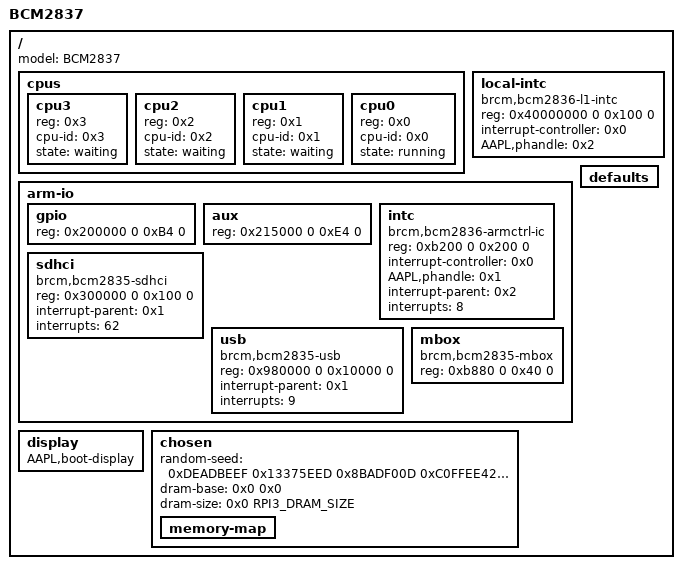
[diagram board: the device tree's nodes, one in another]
/dts-v1/;

/*
 * Base tree from FlorentRevest/xnu (devicetrees/rpi3.dts), extended with an
 * SD/MMC controller node and the BCM2836/2837 interrupt controllers.
 *
 * Register offsets/sizes/interrupt cells sourced from upstream Linux:
 *   arch/arm/boot/dts/broadcom/bcm283x.dtsi   (gpio, aux, sdhci, sdhost)
 *   arch/arm/boot/dts/broadcom/bcm2837.dtsi   (local_intc, armctrl-ic override)
 *
 * ROOT CAUSE FOUND AND FIXED (2026-08-13): the <bank irq> 2-cell interrupt
 * encoding this file used to carry over raw from the Linux DT was flagged
 * above as UNVERIFIED, and was in fact wrong - this is very likely why
 * BCM2837SDHCI never observed a real hardware interrupt despite BCM2837CPU's
 * IRQ cascade being otherwise correctly wired (see iokit/BCM2837SDHCI's own
 * "fRealInterruptHits stayed at 0" finding). Traced the real mechanism
 * directly in xnu source (iokit/Kernel/IODeviceTreeSupport.cpp's
 * IODTMapOneInterrupt() + iokit/Kernel/IOInterruptController.cpp's
 * registerInterrupt()): IODTMapOneInterrupt() stores a device's `interrupts`
 * property as a RAW, unmodified OSData blob (all `#interrupt-cells` words,
 * verbatim) - it does NOT combine multi-cell specifiers into anything. The
 * base IOInterruptController::registerInterrupt() then does
 * `vectorNumber = *(IOInterruptVectorNumber *)vectorData->getBytesNoCopy()`
 * - i.e. it blindly takes the FIRST 32-bit cell as the vector number and
 * nothing else, unless the concrete controller subclass overrides
 * registerInterrupt() to do its own multi-cell decode (BCM2837InterruptController
 * does not - see its own header comment, which already flagged this exact
 * gap as unverified). With `#interrupt-cells = <2>` and sdhci's
 * `interrupts = <2 30>`, this meant BCM2837SDHCI's real registered vector
 * number was **2** (the bare first cell) - landing in BCM2837InterruptController's
 * bank-1 range, nowhere near the real hardware bit (bank 2, bit 30 = flat
 * vector 62, per that driver's own bank*32+bit numbering) - so even if the
 * real interrupt line fires, it dispatches to a vector nothing ever
 * registered against, and is silently dropped. Fixed by making `intc`
 * single-cell (`#interrupt-cells = <1>`) and pre-flattening every consumer's
 * `interrupts` property to the already-combined vector number instead -
 * matches what `local-intc`'s own single-cell `interrupts = <8>` already
 * did correctly (single-cell is exactly what the base class's naive
 * first-cell-as-vector-number behavior needs), and avoids having to
 * override IOInterruptController::registerInterrupt() (large, sharing/
 * locking-sensitive base-class code) just to teach it a 2-cell convention.
 */

/ {
	#address-cells = <2>;
	#size-cells = <2>;

	/* Real, unmodified Apple IODTPlatformExpert::getMachineName()
	 * (iokit/Kernel/IOPlatformExpert.cpp) reads this exact property
	 * (gIODTModelKey == "model") off the root node's provider and
	 * returns false -- not a stub, real deprecated-but-still-live
	 * logic -- when it's absent, which is exactly what
	 * bsd/kern/kern_mib.c's real HW_MACHINE sysctl handler treats as a
	 * hard EINVAL (this board takes that file's non-XNU_TARGET_OS_OSX
	 * branch, since BCM2837 builds embedded/iPhoneOS, not macOS -- see
	 * CLAUDE.md). Found via a real QEMU boot-test: `uname`'s real,
	 * unmodified Apple source (third_party/shell_cmds/uname/uname.c)
	 * calls uname(2)'s real sysctl(CTL_HW, HW_MACHINE, ...) path and
	 * got a genuine EINVAL back, confirmed via a scratch sysctl_probe
	 * that isolated it to this exact MIB (KERN_OSTYPE/HOSTNAME/
	 * OSRELEASE/VERSION all real-succeeded). Not a userland bug --
	 * this synthetic device tree was simply missing a property real
	 * hardware's firmware-provided DT always carries. */
	model = "BCM2837";

	cpus {
		#address-cells = <1>;
		#size-cells = <0>;

		/*
		 * DAR-455. All four Cortex-A53 cores. `reg` is the core's
		 * MPIDR_EL1 Aff0 (QEMU: hw/arm/bcm2836.c mp_affinity = core,
		 * clusterid 0 for bcm2837; Linux/u-boot bcm2837.dtsi uses
		 * reg = <0>..<3> for the same cores). XNU uses it as the CPU's
		 * phys_id (osfmk/arm64/machine_routines.c ml_parse_cpu_topology)
		 * and the reset vector finds a waking core's cpu_data by
		 * comparing MPIDR & 0xff against it (osfmk/arm64/start.s).
		 * cpu0's reg used to be 0xf00 (a BCM2836/Cortex-A7 MPIDR); it was
		 * never consumed: the node had no device_type, so createNubs()
		 * never looked it up, and BCM2837CPU hard-coded phys_id 0.
		 *
		 * device_type = "cpu" makes IODTPlatformExpert::createNubs()
		 * attach "logical-cpu-id" to each nub the kernel's topology kept
		 * (iokit/Kernel/IOPlatformExpert.cpp). On BCM2837 the kernel
		 * keeps only cpu0 unless booted with cpus=N, so cpu1-3 are inert
		 * by default.
		 */
		/*
		 * Listed cpu3 -> cpu0 ON PURPOSE: dtc-AppleDeviceTree emits a
		 * node's children in reverse source order (checked with
		 * `strings rpi3.dtb`: the first build had "waiting" x3 before
		 * "running"), and XNU numbers CPUs in blob order
		 * (ml_parse_cpu_topology()). Reversed here, the blob holds cpu0
		 * first, so logical CPU N is core N and the boot CPU is CPU 0.
		 * In source order the first QEMU try gave the boot CPU logical
		 * id 3.
		 */
		cpu3 {
			device_type = "cpu";
			reg = <0x3>;
			cpu-id = <0x3>;
			state = "waiting";
		};

		cpu2 {
			device_type = "cpu";
			reg = <0x2>;
			cpu-id = <0x2>;
			state = "waiting";
		};

		cpu1 {
			device_type = "cpu";
			reg = <0x1>;
			cpu-id = <0x1>;
			state = "waiting";
		};

		cpu0 {
			device_type = "cpu";
			reg = <0x0>;
			cpu-id = <0x0>;
			state = "running";
		};
	};

	/*
	 * BCM2836/2837 L1 interrupt controller ("local_intc" in Linux DT).
	 * Lives at a fixed physical address outside the 0x7e000000 VC/GPU
	 * peripheral bus window, so it's a root sibling rather than a child
	 * of arm-io (its address wouldn't translate through arm-io's single
	 * ranges entry below). Handles per-CPU timer/PMU/mailbox IRQs and
	 * takes IRQ 8 from the global armctrl-ic as its "GPU interrupt" line.
	 */
	local-intc {
		device_type = "interrupt-controller";
		compatible = "brcm,bcm2836-l1-intc";
		reg = <0x40000000 0 0x100 0>;
		/*
		 * FIX (found wiring BCM2837InterruptController's own upstream
		 * interrupt): needed so IODTFindInterruptParent()/
		 * IODTMapOneInterrupt() (iokit/Kernel/IODeviceTreeSupport.cpp)
		 * can resolve "intc"'s `interrupt-parent = <0x2>` below to a
		 * terminal controller and compute the symbol
		 * BCM2837InterruptController::start() must register itself
		 * under - AAPL,phandle for FindPHandle(), the
		 * "interrupt-controller" boolean marker so the walk stops here
		 * instead of following gIODTPlane up to root, #interrupt-cells
		 * so "intc"'s single-cell `interrupts = <8>` below is sized
		 * correctly (IRQ 8 = the "GPU interrupt" line per Linux's
		 * bcm2836-l1-intc.dtsi convention, matching this node's own
		 * header comment above).
		 */
		interrupt-controller = <0x0>;
		AAPL,phandle = <0x2>;
		#interrupt-cells = <1>;
	};

	arm-io {
		device_type = "bcm2837-io";
		/*
		 * FIX (found booting BCM2837InterruptController/BCM2837SDHCI for
		 * real): child-base was 0x7e000000, but every child node's own
		 * "reg" below is written as a bare VC-bus *offset* (0xb200,
		 * 0x300000, ...), not the full VC address (0x7e00b200,
		 * 0x7e300000, ...). Standard OF ranges translation requires
		 * child reg values to fall within [child-base, child-base+size)
		 * - with child-base=0x7e000000, every one of these offsets was
		 * numerically far below that window, so IODTResolveAddressing()
		 * (iokit/Kernel/IODeviceTreeSupport.cpp) could never find a
		 * match and every device's mapDeviceMemoryWithIndex() failed
		 * (confirmed: "BCM2837InterruptController: failed to map
		 * \"intc\" registers" at boot). child-base=0 makes translation
		 * `child_reg - 0 + 0x3f000000`, e.g. intc's 0xb200 -> 0x3f00b200
		 * - exactly the physical address BCM2837InterruptController.h's
		 * own header comment already documented as correct.
		 */
		ranges = <0 0 0x3f000000 0 0x1000000 0>;

		#address-cells = <2>;
		#size-cells = <2>;

		gpio { reg = <0x200000 0 0xB4 0>; };
		aux  { reg = <0x215000 0 0xE4 0>; };

		/*
		 * Global/GPU interrupt controller ("armctrl-ic"). All
		 * VC-bus peripheral IRQs (gpio, aux, sdhci, ...) route
		 * through here before reaching local-intc on IRQ 8.
		 */
		intc {
			device_type = "interrupt-controller";
			compatible = "brcm,bcm2836-armctrl-ic";
			reg = <0xb200 0 0x200 0>;
			/*
			 * IODeviceTreeSupport.cpp's IODTFindInterruptParent()
			 * checks for a property literally named
			 * "interrupt-controller" (boolean marker, Linux DT
			 * convention) - device_type above does NOT satisfy
			 * this check, it's a separate mechanism. Phandle
			 * lookups go through Apple's own "AAPL,phandle" (not
			 * the standard "phandle") per gIODTPHandleKey.
			 */
			interrupt-controller = <0x0>;
			AAPL,phandle = <0x1>;
			// Single-cell, pre-flattened vector numbers - see the file
			// header comment ("ROOT CAUSE FOUND AND FIXED") for why this
			// changed from <2> (bank, bit) - the base IOInterruptController
			// registerInterrupt() only ever reads a multi-cell specifier's
			// first word as the vector number, so a 2-cell {bank,bit}
			// convention silently registered every consumer against the
			// wrong vector (bank value only) without a custom decode this
			// controller never implemented.
			#interrupt-cells = <1>;
			#address-cells = <0>;
			/*
			 * FIX: intc's own upstream interrupt (cascaded from
			 * local-intc's "GPU interrupt" line, IRQ 8 - see
			 * local-intc's header comment above) - without this,
			 * BCM2837InterruptController::start()'s
			 * provider->registerInterrupt(0, ...) call (against the
			 * "intc" nub itself) has no interrupt-parent to resolve
			 * and fails outright (confirmed empirically: 0xe00002be).
			 * interrupt-parent points at local-intc's AAPL,phandle
			 * (0x2); the single cell in `interrupts` is sized by
			 * local-intc's own #interrupt-cells=<1> above.
			 */
			interrupt-parent = <0x2>;
			interrupts = <8>;
		};

		/*
		 * Arasan SDHCI controller (Linux: sdhci@7e300000,
		 * "brcm,bcm2835-sdhci"). On stock firmware this is wired to
		 * the onboard SDIO WiFi (GPIO34-39, ALT3) rather than the
		 * physical SD slot. To reach the SD card instead, GPIO48-53
		 * must be muxed to ALT3 ("emmc_gpio48" in Linux DT) instead
		 * of ALT0 (which routes them to the "sdhost" controller at
		 * VC offset 0x202000 / size 0x100, interrupts <2 24> - the
		 * default owner of the physical slot, but a Broadcom-
		 * proprietary register layout with no public reference
		 * outside the Linux driver).
		 */
		sdhci {
			device_type = "sdhci";
			compatible = "brcm,bcm2835-sdhci";
			reg = <0x300000 0 0x100 0>;
			interrupt-parent = <0x1>;
			// Pre-flattened: real bank 2 ("pending_2", GPU IRQs 32-63),
			// bit 30 -> BCM2837InterruptController's own
			// kVectorBank2Base(32) + 30 = vector 62. Was <2 30> (raw
			// 2-cell bank/bit) - see "intc" node's own comment above for
			// why that never actually worked.
			interrupts = <62>;
		};

		/*
		 * Synopsys DesignWare USB 2.0 OTG host controller ("dwc2").
		 * Linux/u-boot: usb@7e980000, compatible "brcm,bcm2835-usb",
		 * reg <0x7e980000 0x10000>, interrupts <1 9> - verified against
		 * third_party/u-boot/arch/arm/dts/bcm283x.dtsi:626, not from
		 * memory.
		 *
		 * This is the Pi 3's *only* USB controller, and the SMSC LAN9514
		 * (USB hub + Ethernet in one chip) is hard-wired to its root
		 * port, so this node gates all of Phase 6 networking - see
		 * docs/usb-support-plan.md.
		 *
		 * The register window is 0x10000 (matching Linux/u-boot), not
		 * QEMU's slightly larger 0x11000 container region: 0x0000-0x0fff
		 * is the hsotg core/host register block this driver actually
		 * uses, 0x1000+ is the per-channel FIFO space used only in slave
		 * (non-DMA) mode. 0x10000 is correct on real hardware and is a
		 * strict subset of what QEMU maps, so it is right for both.
		 *
		 * u-boot's second reg entry (<0x7e00b200 0x200>, the MPHI
		 * peripheral) is deliberately omitted: it exists only so Linux's
		 * dwc_otg FIQ fast-path can generate a spurious interrupt to
		 * kick its own softirq, which this driver does not implement.
		 */
		usb {
			device_type = "usb";
			compatible = "brcm,bcm2835-usb";
			reg = <0x980000 0 0x10000 0>;
			interrupt-parent = <0x1>;
			// Pre-flattened, same convention as sdhci above: u-boot's raw
			// 2-cell <1 9> means bank 1 ("pending_1", GPU IRQs 0-31) bit 9,
			// so BCM2837InterruptController's own
			// kVectorBank1Base(0) + 9 = vector 9. See the "intc" node's
			// comment for why the raw 2-cell form never worked here.
			interrupts = <9>;
		};

		/*
		 * VideoCore mailbox (Linux: mailbox@7e00b880,
		 * "brcm,bcm2835-mbox"). Used by pexpert/arm/pe_init.c's
		 * bcm2837_video_init() to request an HDMI framebuffer from the
		 * GPU firmware via the property-tag protocol before
		 * PE_create_console() runs. Size 0x40 covers both mailbox 0
		 * (read, offset 0x00) and mailbox 1 (write, offset 0x20)
		 * register blocks - see Linux's drivers/mailbox/bcm2835-mailbox.c.
		 */
		mbox {
			device_type = "mbox";
			compatible = "brcm,bcm2835-mbox";
			reg = <0xb880 0 0x40 0>;
		};
	};

	/*
	 * DAR-331: the HDMI boot display, as its own nub for IOGraphics'
	 * IOBootFramebuffer to match. That class's probe() requires the
	 * property "AAPL,boot-display" on its PROVIDER
	 * (third_party/IOGraphics/IOGraphicsFamily/IOBootFramebuffer.cpp:50),
	 * then independently checks getConsoleInfo()'s v_baseAddr != 0
	 * (:53-55) -- so a headless boot, where pexpert/arm/pe_init.c's
	 * bcm2837_video_init() found no framebuffer, still correctly fails
	 * to match even though this node is static.
	 *
	 * A top-level node because IODTPlatformExpert::createNubs()
	 * (iokit/Kernel/IOPlatformExpert.cpp) registerService()s every
	 * top-level child as an IOPlatformDevice. Setting the property on
	 * the platform expert itself (DAR-331 step 1's first attempt) could
	 * never match anything: nothing ever registerService()s the PE.
	 * On real Macs the property likewise sits on the display device's
	 * own nub (the GPU's PCI nub), not on the platform expert.
	 */
	display {
		device_type = "display";
		AAPL,boot-display;
	};

	chosen {
		random-seed = <0xDEADBEEF 0x13375EED 0x8BADF00D 0xC0FFEE42 0x5A17BE55 0x9E3779B9 0xF00DFACE 0x2545F491 0x1B873593 0x85EBCA6B 0xC2B2AE35 0x27D4EB2F 0x165667B1 0xD3A2646C 0xFD7046C5 0xB55A4F09>;

		/*
		 * arm_init() (osfmk/arm64/arm_init.c in the source this kernel was
		 * built from) hard-requires these two directly under chosen, read
		 * as 8-byte values (disassembly of arm_init confirms two 64-bit
		 * ldr's into dram_base/dram_size globals via
		 * SecureDTGetPropertyInternal). Real BCM2837 DRAM starts at
		 * physical 0x0 - dram-size matches boot_args.memSize, i.e.
		 * QEMU's -m size minus the 64MB VC/GPU carve-out
		 * (DEFAULT_VCRAM_SIZE in hw/display/bcm2835_fb.c). Recompute if
		 * -m changes: dram-size = (m_megabytes * 0x100000) - 0x4000000.
		 */
		dram-base = <0x0 0x0>;
		/*
		 * The QEMU value. rpi3-realhw.dts #includes this file and
		 * pre-defines RPI3_DRAM_SIZE to its own board value - that is
		 * the ONLY property the two trees differ in, and doing it this
		 * way is what stops the real-hardware tree going stale again
		 * (it did, twice - see rpi3-realhw.dts's header).
		 */
#ifndef RPI3_DRAM_SIZE
#define RPI3_DRAM_SIZE 0x3C000000
#endif
		dram-size = <0x0 RPI3_DRAM_SIZE>;

		memory-map { };
	};

	defaults { };
};
